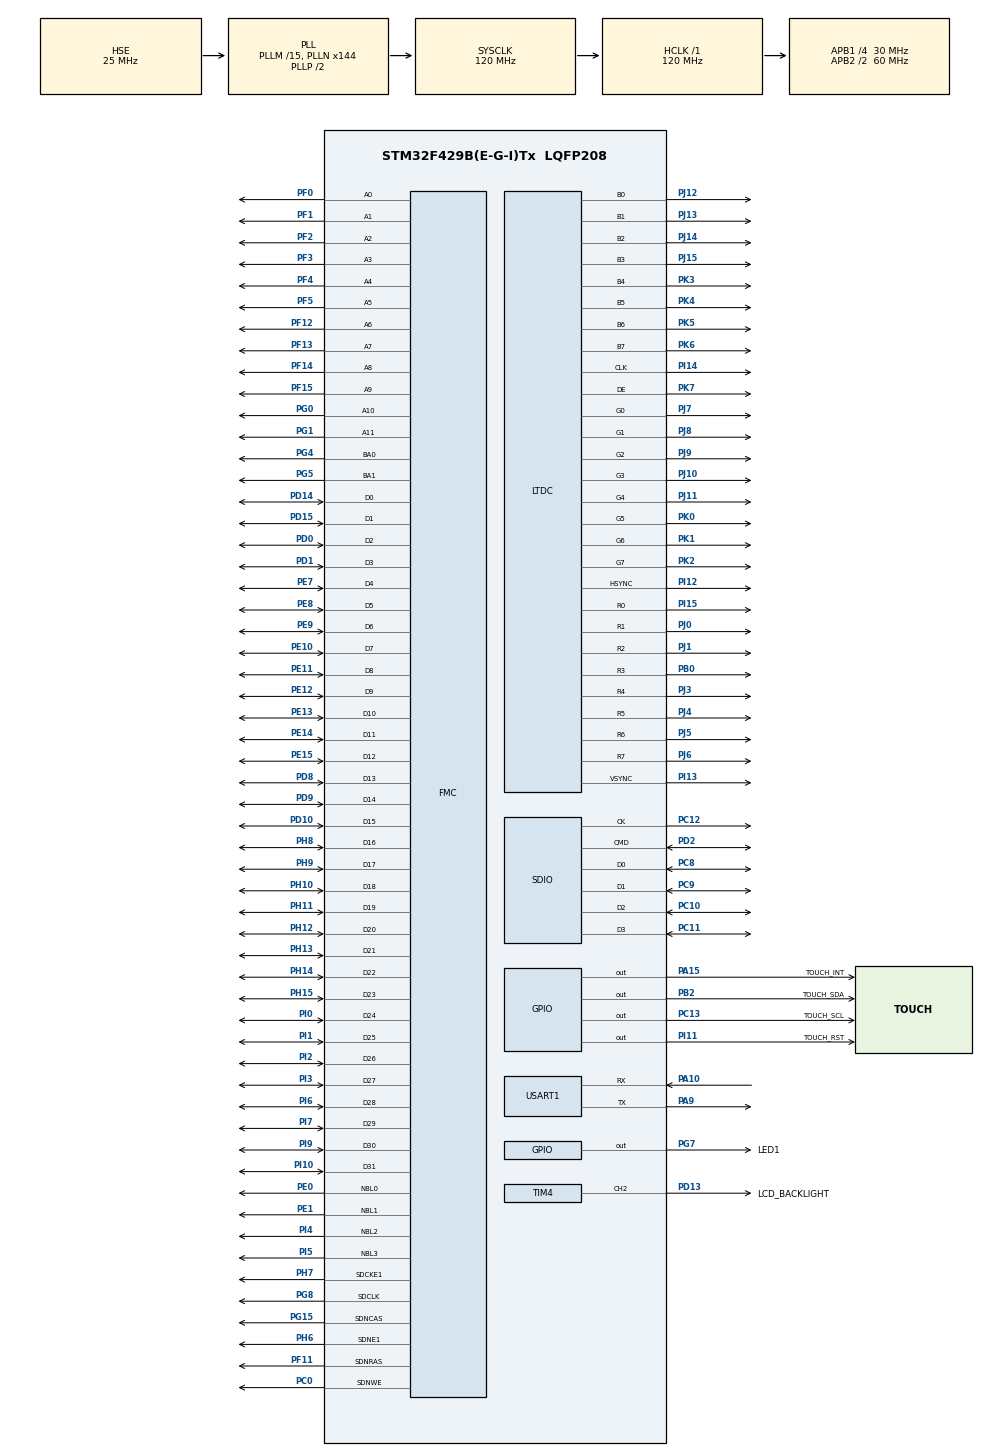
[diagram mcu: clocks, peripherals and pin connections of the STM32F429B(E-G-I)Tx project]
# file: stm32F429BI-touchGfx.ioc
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DMA2D.ColorMode=DMA2D_OUTPUT_RGB888
FMC.CASLatency1=FMC_SDRAM_CAS_LATENCY_3
FMC.ExitSelfRefreshDelay1=7
FMC.LoadToActiveDelay1=2
FMC.RCDDelay1=2
FMC.RPDelay1=2
FMC.RPDelay2=2
FMC.ReadBurst1=FMC_SDRAM_RBURST_ENABLE
FMC.ReadBurst2=FMC_SDRAM_RBURST_ENABLE
FMC.ReadPipeDelay1=FMC_SDRAM_RPIPE_DELAY_1
FMC.ReadPipeDelay2=FMC_SDRAM_RPIPE_DELAY_1
FMC.RowCycleDelay1=6
FMC.RowCycleDelay2=6
FMC.SDClockPeriod1=FMC_SDRAM_CLOCK_PERIOD_2
FMC.SDClockPeriod2=FMC_SDRAM_CLOCK_PERIOD_2
FMC.SelfRefreshTime1=4
FMC.WriteRecoveryTime1=2
FREERTOS.Tasks01=defaultTask,0,2048,StartDefaultTask,Default,NULL,Dynamic,NULL,NULL;blinkLed,-3,128,blinkingLed,Default,NULL,Dynamic,NULL,NULL
LTDC.ActiveW=800
LTDC.Alpha_L0=255
LTDC.FBStartAdress_L0=0xD0000000
LTDC.HBP=75
LTDC.HFP=180
LTDC.HSync=2
LTDC.ImageHeight_L0=480
LTDC.ImageWidth_L0=800
LTDC.Layers=0
LTDC.PixelFormat_L0=LTDC_PIXEL_FORMAT_RGB888
LTDC.VBP=22
LTDC.VFP=22
LTDC.VSync=2
LTDC.WindowX0_L0=0
LTDC.WindowX1_L0=800
LTDC.WindowY0_L0=0
LTDC.WindowY1_L0=480
Mcu.Family=STM32F4
Mcu.Name=STM32F429B(E-G-I)Tx
Mcu.Package=LQFP208
NVIC.DMA2D_IRQn=true\:5\:0\:false\:false\:true\:true\:true\:true
NVIC.LTDC_IRQn=true\:5\:0\:false\:false\:true\:true\:true\:true
NVIC.PriorityGroup=NVIC_PRIORITYGROUP_4
NVIC.SDIO_IRQn=true\:5\:0\:false\:false\:true\:true\:true\:true
NVIC.TIM1_UP_TIM10_IRQn=true\:0\:0\:false\:false\:true\:false\:false\:true
NVIC.TimeBase=TIM1_UP_TIM10_IRQn
NVIC.TimeBaseIP=TIM1
NVIC.USART1_IRQn=true\:5\:0\:false\:false\:true\:true\:true\:true
PA10.Mode=Asynchronous
PA10.Signal=USART1_RX
PA15.GPIO_Label=TOUCH_INT
PA15.GPIO_ModeDefaultOutputPP=GPIO_MODE_OUTPUT_OD
PA15.GPIO_PuPd=GPIO_NOPULL
PA15.PinState=GPIO_PIN_SET
PA15.Signal=GPIO_Output
PA9.Mode=Asynchronous
PA9.Signal=USART1_TX
PB0.Mode=RGB888
PB0.Signal=LTDC_R3
PB2/BOOT1.GPIO_Label=TOUCH_SDA
PB2/BOOT1.GPIO_ModeDefaultOutputPP=GPIO_MODE_OUTPUT_OD
PB2/BOOT1.GPIO_PuPd=GPIO_NOPULL
PB2/BOOT1.GPIO_Speed=GPIO_SPEED_FREQ_MEDIUM
PB2/BOOT1.PinState=GPIO_PIN_SET
PB2/BOOT1.Signal=GPIO_Output
PC0.Signal=FMC_SDNWE
PC10.Mode=SD_4_bits_Wide_bus
PC10.Signal=SDIO_D2
PC11.Mode=SD_4_bits_Wide_bus
PC11.Signal=SDIO_D3
PC12.Mode=SD_4_bits_Wide_bus
PC12.Signal=SDIO_CK
PC13.GPIO_Label=TOUCH_SCL
PC13.GPIO_ModeDefaultOutputPP=GPIO_MODE_OUTPUT_OD
PC13.GPIO_PuPd=GPIO_NOPULL
PC13.PinState=GPIO_PIN_SET
PC13.Signal=GPIO_Output
PC14/OSC32_IN.Mode=LSE-External-Oscillator
PC14/OSC32_IN.Signal=RCC_OSC32_IN
PC15/OSC32_OUT.Mode=LSE-External-Oscillator
PC15/OSC32_OUT.Signal=RCC_OSC32_OUT
PC8.Mode=SD_4_bits_Wide_bus
PC8.Signal=SDIO_D0
PC9.Mode=SD_4_bits_Wide_bus
PC9.Signal=SDIO_D1
PD0.Signal=FMC_D2_DA2
PD1.Signal=FMC_D3_DA3
PD10.Signal=FMC_D15_DA15
PD13.GPIO_Label=LCD_BACKLIGHT
PD13.GPIO_Speed=GPIO_SPEED_FREQ_HIGH
PD13.Signal=S_TIM4_CH2
PD14.Signal=FMC_D0_DA0
PD15.Signal=FMC_D1_DA1
PD2.Mode=SD_4_bits_Wide_bus
PD2.Signal=SDIO_CMD
PD8.Signal=FMC_D13_DA13
PD9.Signal=FMC_D14_DA14
PE0.Signal=FMC_NBL0
PE1.Signal=FMC_NBL1
PE10.Signal=FMC_D7_DA7
PE11.Signal=FMC_D8_DA8
PE12.Signal=FMC_D9_DA9
PE13.Signal=FMC_D10_DA10
PE14.Signal=FMC_D11_DA11
PE15.Signal=FMC_D12_DA12
PE7.Signal=FMC_D4_DA4
PE8.Signal=FMC_D5_DA5
PE9.Signal=FMC_D6_DA6
PF0.Signal=FMC_A0
PF1.Signal=FMC_A1
PF11.Signal=FMC_SDNRAS
PF12.Signal=FMC_A6
PF13.Signal=FMC_A7
PF14.Signal=FMC_A8
PF15.Signal=FMC_A9
PF2.Signal=FMC_A2
PF3.Signal=FMC_A3
PF4.Signal=FMC_A4
PF5.Signal=FMC_A5
PG0.Signal=FMC_A10
PG1.Signal=FMC_A11
PG15.Signal=FMC_SDNCAS
PG4.Signal=FMC_A14_BA0
PG5.Signal=FMC_A15_BA1
PG7.GPIO_Label=LED1
PG7.Signal=GPIO_Output
PG8.Signal=FMC_SDCLK
PH0/OSC_IN.Mode=HSE-External-Oscillator
PH0/OSC_IN.Signal=RCC_OSC_IN
PH1/OSC_OUT.Mode=HSE-External-Oscillator
PH1/OSC_OUT.Signal=RCC_OSC_OUT
PH10.Signal=FMC_D18
PH11.Signal=FMC_D19
PH12.Signal=FMC_D20
PH13.Signal=FMC_D21
PH14.Signal=FMC_D22
PH15.Signal=FMC_D23
PH6.Mode=SdramChipSelect2_1
PH6.Signal=FMC_SDNE1
PH7.Mode=SdramChipSelect2_1
PH7.Signal=FMC_SDCKE1
PH8.Signal=FMC_D16
PH9.Signal=FMC_D17
PI0.Signal=FMC_D24
PI1.Signal=FMC_D25
PI10.Signal=FMC_D31
PI11.GPIO_Label=TOUCH_RST
PI11.GPIO_ModeDefaultOutputPP=GPIO_MODE_OUTPUT_OD
PI11.GPIO_PuPd=GPIO_NOPULL
PI11.GPIO_Speed=GPIO_SPEED_FREQ_MEDIUM
PI11.PinState=GPIO_PIN_SET
PI11.Signal=GPIO_Output
PI12.Mode=RGB888
PI12.Signal=LTDC_HSYNC
PI13.Mode=RGB888
PI13.Signal=LTDC_VSYNC
PI14.Mode=RGB888
PI14.Signal=LTDC_CLK
PI15.Mode=RGB888
PI15.Signal=LTDC_R0
PI2.Signal=FMC_D26
PI3.Signal=FMC_D27
PI4.Signal=FMC_NBL2
PI5.Signal=FMC_NBL3
PI6.Signal=FMC_D28
PI7.Signal=FMC_D29
PI9.Signal=FMC_D30
PJ0.Mode=RGB888
PJ0.Signal=LTDC_R1
PJ1.Mode=RGB888
PJ1.Signal=LTDC_R2
PJ10.Mode=RGB888
PJ10.Signal=LTDC_G3
PJ11.Mode=RGB888
PJ11.Signal=LTDC_G4
PJ12.Mode=RGB888
PJ12.Signal=LTDC_B0
PJ13.Mode=RGB888
PJ13.Signal=LTDC_B1
PJ14.Mode=RGB888
PJ14.Signal=LTDC_B2
PJ15.Mode=RGB888
PJ15.Signal=LTDC_B3
PJ3.Mode=RGB888
PJ3.Signal=LTDC_R4
PJ4.Mode=RGB888
PJ4.Signal=LTDC_R5
PJ5.Mode=RGB888
PJ5.Signal=LTDC_R6
PJ6.Mode=RGB888
PJ6.Signal=LTDC_R7
PJ7.Mode=RGB888
PJ7.Signal=LTDC_G0
PJ8.Mode=RGB888
PJ8.Signal=LTDC_G1
PJ9.Mode=RGB888
PJ9.Signal=LTDC_G2
PK0.Mode=RGB888
PK0.Signal=LTDC_G5
PK1.Mode=RGB888
PK1.Signal=LTDC_G6
PK2.Mode=RGB888
PK2.Signal=LTDC_G7
PK3.Mode=RGB888
PK3.Signal=LTDC_B4
PK4.Mode=RGB888
PK4.Signal=LTDC_B5
PK5.Mode=RGB888
PK5.Signal=LTDC_B6
PK6.Mode=RGB888
PK6.Signal=LTDC_B7
PK7.Mode=RGB888
PK7.Signal=LTDC_DE
ProjectManager.HeapSize=0x200
ProjectManager.StackSize=0x400
ProjectManager.TargetToolchain=STM32CubeIDE
RCC.48MHZClocksFreq_Value=48000000
RCC.AHBFreq_Value=120000000
RCC.APB1CLKDivider=RCC_HCLK_DIV4
RCC.APB1Freq_Value=30000000
RCC.APB1TimFreq_Value=60000000
RCC.APB2CLKDivider=RCC_HCLK_DIV2
RCC.APB2Freq_Value=60000000
RCC.APB2TimFreq_Value=120000000
RCC.CortexFreq_Value=120000000
RCC.HCLKFreq_Value=120000000
RCC.HSE_VALUE=25000000
RCC.HSI_VALUE=16000000
RCC.PLLM=15
RCC.PLLN=144
RCC.PLLQ=5
RCC.PLLSAIN=60
RCC.PLLSourceVirtual=RCC_PLLSOURCE_HSE
RCC.SYSCLKFreq_VALUE=120000000
RCC.SYSCLKSource=RCC_SYSCLKSOURCE_PLLCLK
RCC.VCOOutputFreq_Value=240000000
SH.FMC_A0.0=FMC_A0,12b-sda1
SH.FMC_A1.0=FMC_A1,12b-sda1
SH.FMC_A10.0=FMC_A10,12b-sda1
SH.FMC_A11.0=FMC_A11,12b-sda1
SH.FMC_A14_BA0.0=FMC_BA0,FourSdramBanks1
SH.FMC_A15_BA1.0=FMC_BA1,FourSdramBanks1
SH.FMC_A2.0=FMC_A2,12b-sda1
SH.FMC_A3.0=FMC_A3,12b-sda1
SH.FMC_A4.0=FMC_A4,12b-sda1
SH.FMC_A5.0=FMC_A5,12b-sda1
SH.FMC_A6.0=FMC_A6,12b-sda1
SH.FMC_A7.0=FMC_A7,12b-sda1
SH.FMC_A8.0=FMC_A8,12b-sda1
SH.FMC_A9.0=FMC_A9,12b-sda1
SH.FMC_D0_DA0.0=FMC_D0,sd-32b-d1
SH.FMC_D10_DA10.0=FMC_D10,sd-32b-d1
SH.FMC_D11_DA11.0=FMC_D11,sd-32b-d1
SH.FMC_D12_DA12.0=FMC_D12,sd-32b-d1
SH.FMC_D13_DA13.0=FMC_D13,sd-32b-d1
SH.FMC_D14_DA14.0=FMC_D14,sd-32b-d1
SH.FMC_D15_DA15.0=FMC_D15,sd-32b-d1
SH.FMC_D16.0=FMC_D16,sd-32b-d1
SH.FMC_D17.0=FMC_D17,sd-32b-d1
SH.FMC_D18.0=FMC_D18,sd-32b-d1
SH.FMC_D19.0=FMC_D19,sd-32b-d1
SH.FMC_D1_DA1.0=FMC_D1,sd-32b-d1
SH.FMC_D20.0=FMC_D20,sd-32b-d1
SH.FMC_D21.0=FMC_D21,sd-32b-d1
SH.FMC_D22.0=FMC_D22,sd-32b-d1
SH.FMC_D23.0=FMC_D23,sd-32b-d1
SH.FMC_D24.0=FMC_D24,sd-32b-d1
SH.FMC_D25.0=FMC_D25,sd-32b-d1
SH.FMC_D26.0=FMC_D26,sd-32b-d1
SH.FMC_D27.0=FMC_D27,sd-32b-d1
SH.FMC_D28.0=FMC_D28,sd-32b-d1
SH.FMC_D29.0=FMC_D29,sd-32b-d1
SH.FMC_D2_DA2.0=FMC_D2,sd-32b-d1
SH.FMC_D30.0=FMC_D30,sd-32b-d1
SH.FMC_D31.0=FMC_D31,sd-32b-d1
SH.FMC_D3_DA3.0=FMC_D3,sd-32b-d1
SH.FMC_D4_DA4.0=FMC_D4,sd-32b-d1
SH.FMC_D5_DA5.0=FMC_D5,sd-32b-d1
SH.FMC_D6_DA6.0=FMC_D6,sd-32b-d1
SH.FMC_D7_DA7.0=FMC_D7,sd-32b-d1
SH.FMC_D8_DA8.0=FMC_D8,sd-32b-d1
SH.FMC_D9_DA9.0=FMC_D9,sd-32b-d1
SH.FMC_NBL0.0=FMC_NBL0,Sd4ByteEnable1
SH.FMC_NBL1.0=FMC_NBL1,Sd4ByteEnable1
SH.FMC_NBL2.0=FMC_NBL2,Sd4ByteEnable1
SH.FMC_NBL3.0=FMC_NBL3,Sd4ByteEnable1
SH.FMC_SDCLK.0=FMC_SDCLK,12b-sda1
SH.FMC_SDNCAS.0=FMC_SDNCAS,12b-sda1
SH.FMC_SDNRAS.0=FMC_SDNRAS,12b-sda1
SH.FMC_SDNWE.0=FMC_SDNWE,12b-sda1
SH.S_TIM4_CH2.0=TIM4_CH2,PWM Generation2 CH2
STMicroelectronics.X-CUBE-TOUCHGFX.4.13.0.ApplicationCcGraphicsJjApplication=TouchGFXOoGenerator
STMicroelectronics.X-CUBE-TOUCHGFX.4.13.0.tgfx_address1=0xD0000000
STMicroelectronics.X-CUBE-TOUCHGFX.4.13.0.tgfx_custom_height=480
STMicroelectronics.X-CUBE-TOUCHGFX.4.13.0.tgfx_display_interface=disp_ltdc
STMicroelectronics.X-CUBE-TOUCHGFX.4.13.0.tgfx_hardware_accelerator=dma_2d
STMicroelectronics.X-CUBE-TOUCHGFX.4.13.0.tgfx_location=By Address
STMicroelectronics.X-CUBE-TOUCHGFX.4.13.0.tgfx_ltdc_height=480
STMicroelectronics.X-CUBE-TOUCHGFX.4.13.0.tgfx_ltdc_width=800
STMicroelectronics.X-CUBE-TOUCHGFX.4.13.0.tgfx_pixel_format=RGB888\:24
STMicroelectronics.X-CUBE-TOUCHGFX.4.13.0.tgfx_vsync=vsync_ltdc
TIM4.AutoReloadPreload=TIM_AUTORELOAD_PRELOAD_DISABLE
TIM4.Channel-PWM\ Generation2\ CH2=TIM_CHANNEL_2
TIM4.OC2Preload_PWM=DISABLE
TIM4.OCFastMode_PWM-PWM\ Generation2\ CH2=TIM_OCFAST_ENABLE
TIM4.Period=1024
TIM4.Prescaler=15
TIM4.Pulse-PWM\ Generation2\ CH2=512
USART1.VirtualMode=VM_ASYNC
VP_CRC_VS_CRC.Mode=CRC_Activate
VP_DMA2D_VS_DMA2D.Mode=DMA2D_Activate
VP_FREERTOS_VS_CMSIS_V1.Mode=CMSIS_V1
VP_STMicroelectronics.X-CUBE-TOUCHGFX_VS_GraphicsJjApplication_4.13.0.Mode=GraphicsJjApplication
VP_SYS_VS_tim1.Mode=TIM1
VP_TIM4_VS_ClockSourceINT.Mode=Internal
board=custom

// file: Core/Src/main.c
/* USER CODE BEGIN Header */
/**
  ******************************************************************************
  * @file           : main.c
  * @brief          : Main program body
  ******************************************************************************
  * @attention
  *
  * <h2><center>&copy; Copyright (c) 2020 STMicroelectronics.
  * All rights reserved.</center></h2>
  *
  * This software component is licensed by ST under BSD 3-Clause license,
  * the "License"; You may not use this file except in compliance with the
  * License. You may obtain a copy of the License at:
  *                        opensource.org/licenses/BSD-3-Clause
  *
  ******************************************************************************
  */
/* USER CODE END Header */

#include "main.h"
#include "cmsis_os.h"
#include "app_touchgfx.h"

/* USER CODE BEGIN PD */
#define REFRESH_COUNT        1386
#define SDRAM_BANK_ADDR     ((uint32_t)0xD0000000)                      // FMC SDRAM address
#define SDRAM_Size 0x01000000  //16MB

#define SDRAM_TIMEOUT                            ((uint32_t)0xFFFF)
#define SDRAM_MODEREG_BURST_LENGTH_1             ((uint16_t)0x0000)
#define SDRAM_MODEREG_BURST_LENGTH_2             ((uint16_t)0x0001)
#define SDRAM_MODEREG_BURST_LENGTH_4             ((uint16_t)0x0002)
#define SDRAM_MODEREG_BURST_LENGTH_8             ((uint16_t)0x0004)
#define SDRAM_MODEREG_BURST_TYPE_SEQUENTIAL      ((uint16_t)0x0000)
#define SDRAM_MODEREG_BURST_TYPE_INTERLEAVED     ((uint16_t)0x0008)
#define SDRAM_MODEREG_CAS_LATENCY_2              ((uint16_t)0x0020)
#define SDRAM_MODEREG_CAS_LATENCY_3              ((uint16_t)0x0030)
#define SDRAM_MODEREG_OPERATING_MODE_STANDARD    ((uint16_t)0x0000)
#define SDRAM_MODEREG_WRITEBURST_MODE_PROGRAMMED ((uint16_t)0x0000)
#define SDRAM_MODEREG_WRITEBURST_MODE_SINGLE     ((uint16_t)0x0200)
/* USER CODE END PD */

CRC_HandleTypeDef hcrc;

DMA2D_HandleTypeDef hdma2d;

LTDC_HandleTypeDef hltdc;

SD_HandleTypeDef hsd;

TIM_HandleTypeDef htim4;

UART_HandleTypeDef huart1;

SDRAM_HandleTypeDef hsdram1;

osThreadId defaultTaskHandle;
osThreadId blinkLedHandle;
/* USER CODE BEGIN PV */
static FMC_SDRAM_CommandTypeDef Command;
/* USER CODE END PV */

void SystemClock_Config(void);
static void MX_GPIO_Init(void);
static void MX_CRC_Init(void);
static void MX_DMA2D_Init(void);
static void MX_FMC_Init(void);
static void MX_LTDC_Init(void);
static void MX_TIM4_Init(void);
static void MX_USART1_UART_Init(void);
static void MX_SDIO_SD_Init(void);
void StartDefaultTask(void const * argument);
void blinkingLed(void const * argument);

int main(void)
{

  /* MCU Configuration--------------------------------------------------------*/

  /* Reset of all peripherals, Initializes the Flash interface and the Systick. */
  HAL_Init();

  /* Configure the system clock */
  SystemClock_Config();

  /* USER CODE BEGIN SysInit */
  SystemCoreClockUpdate(); // from https://support.touchgfx.com/docs/development/board-bring-up/how-to/02-cpu-running
  /* USER CODE END SysInit */

  /* Initialize all configured peripherals */
  MX_GPIO_Init();
  MX_CRC_Init();
  MX_DMA2D_Init();
  MX_FMC_Init();
  MX_LTDC_Init();
  MX_TIM4_Init();
  MX_USART1_UART_Init();
  MX_SDIO_SD_Init();
  MX_TouchGFX_Init();
  /* USER CODE BEGIN 2 */
  printf("System configured!\r\n");
  /* USER CODE END 2 */

  /* Create the thread(s) */
  /* definition and creation of defaultTask */
  osThreadDef(defaultTask, StartDefaultTask, osPriorityNormal, 0, 2048);
  defaultTaskHandle = osThreadCreate(osThread(defaultTask), NULL);

  /* definition and creation of blinkLed */
  osThreadDef(blinkLed, blinkingLed, osPriorityIdle, 0, 128);
  blinkLedHandle = osThreadCreate(osThread(blinkLed), NULL);

  /* Start scheduler */
  osKernelStart();

  /* We should never get here as control is now taken by the scheduler */
  /* Infinite loop */
  while (1)
  {

  }
}

void SystemClock_Config(void)
{
  RCC_OscInitTypeDef RCC_OscInitStruct = {0};
  RCC_ClkInitTypeDef RCC_ClkInitStruct = {0};
  RCC_PeriphCLKInitTypeDef PeriphClkInitStruct = {0};

  /** Configure the main internal regulator output voltage
  */
  __HAL_RCC_PWR_CLK_ENABLE();
  __HAL_PWR_VOLTAGESCALING_CONFIG(PWR_REGULATOR_VOLTAGE_SCALE3);
  /** Initializes the CPU, AHB and APB busses clocks
  */
  RCC_OscInitStruct.OscillatorType = RCC_OSCILLATORTYPE_HSE;
  RCC_OscInitStruct.HSEState = RCC_HSE_ON;
  RCC_OscInitStruct.PLL.PLLState = RCC_PLL_ON;
  RCC_OscInitStruct.PLL.PLLSource = RCC_PLLSOURCE_HSE;
  RCC_OscInitStruct.PLL.PLLM = 15;
  RCC_OscInitStruct.PLL.PLLN = 144;
  RCC_OscInitStruct.PLL.PLLP = RCC_PLLP_DIV2;
  RCC_OscInitStruct.PLL.PLLQ = 5;
  if (HAL_RCC_OscConfig(&RCC_OscInitStruct) != HAL_OK)
  {
    Error_Handler();
  }
  /** Initializes the CPU, AHB and APB busses clocks
  */
  RCC_ClkInitStruct.ClockType = RCC_CLOCKTYPE_HCLK|RCC_CLOCKTYPE_SYSCLK
                              |RCC_CLOCKTYPE_PCLK1|RCC_CLOCKTYPE_PCLK2;
  RCC_ClkInitStruct.SYSCLKSource = RCC_SYSCLKSOURCE_PLLCLK;
  RCC_ClkInitStruct.AHBCLKDivider = RCC_SYSCLK_DIV1;
  RCC_ClkInitStruct.APB1CLKDivider = RCC_HCLK_DIV4;
  RCC_ClkInitStruct.APB2CLKDivider = RCC_HCLK_DIV2;

  if (HAL_RCC_ClockConfig(&RCC_ClkInitStruct, FLASH_LATENCY_3) != HAL_OK)
  {
    Error_Handler();
  }
  PeriphClkInitStruct.PeriphClockSelection = RCC_PERIPHCLK_LTDC;
  PeriphClkInitStruct.PLLSAI.PLLSAIN = 60;
  PeriphClkInitStruct.PLLSAI.PLLSAIR = 2;
  PeriphClkInitStruct.PLLSAIDivR = RCC_PLLSAIDIVR_2;
  if (HAL_RCCEx_PeriphCLKConfig(&PeriphClkInitStruct) != HAL_OK)
  {
    Error_Handler();
  }
}

static void MX_CRC_Init(void)
{

  hcrc.Instance = CRC;
  if (HAL_CRC_Init(&hcrc) != HAL_OK)
  {
    Error_Handler();
  }

}

static void MX_DMA2D_Init(void)
{

  hdma2d.Instance = DMA2D;
  hdma2d.Init.Mode = DMA2D_M2M;
  hdma2d.Init.ColorMode = DMA2D_OUTPUT_RGB888;
  hdma2d.Init.OutputOffset = 0;
  hdma2d.LayerCfg[1].InputOffset = 0;
  hdma2d.LayerCfg[1].InputColorMode = DMA2D_INPUT_RGB888;
  hdma2d.LayerCfg[1].AlphaMode = DMA2D_NO_MODIF_ALPHA;
  hdma2d.LayerCfg[1].InputAlpha = 0;
  if (HAL_DMA2D_Init(&hdma2d) != HAL_OK)
  {
    Error_Handler();
  }
  if (HAL_DMA2D_ConfigLayer(&hdma2d, 1) != HAL_OK)
  {
    Error_Handler();
  }

}

static void MX_LTDC_Init(void)
{

  LTDC_LayerCfgTypeDef pLayerCfg = {0};

  hltdc.Instance = LTDC;
  hltdc.Init.HSPolarity = LTDC_HSPOLARITY_AL;
  hltdc.Init.VSPolarity = LTDC_VSPOLARITY_AL;
  hltdc.Init.DEPolarity = LTDC_DEPOLARITY_AL;
  hltdc.Init.PCPolarity = LTDC_PCPOLARITY_IPC;
  hltdc.Init.HorizontalSync = 1;
  hltdc.Init.VerticalSync = 1;
  hltdc.Init.AccumulatedHBP = 76;
  hltdc.Init.AccumulatedVBP = 23;
  hltdc.Init.AccumulatedActiveW = 876;
  hltdc.Init.AccumulatedActiveH = 503;
  hltdc.Init.TotalWidth = 1056;
  hltdc.Init.TotalHeigh = 525;
  hltdc.Init.Backcolor.Blue = 0;
  hltdc.Init.Backcolor.Green = 0;
  hltdc.Init.Backcolor.Red = 0;
  if (HAL_LTDC_Init(&hltdc) != HAL_OK)
  {
    Error_Handler();
  }
  pLayerCfg.WindowX0 = 0;
  pLayerCfg.WindowX1 = 800;
  pLayerCfg.WindowY0 = 0;
  pLayerCfg.WindowY1 = 480;
  pLayerCfg.PixelFormat = LTDC_PIXEL_FORMAT_RGB888;
  pLayerCfg.Alpha = 255;
  pLayerCfg.Alpha0 = 0;
  pLayerCfg.BlendingFactor1 = LTDC_BLENDING_FACTOR1_CA;
  pLayerCfg.BlendingFactor2 = LTDC_BLENDING_FACTOR2_CA;
  pLayerCfg.FBStartAdress = 0xD0000000;
  pLayerCfg.ImageWidth = 800;
  pLayerCfg.ImageHeight = 480;
  pLayerCfg.Backcolor.Blue = 0;
  pLayerCfg.Backcolor.Green = 0;
  pLayerCfg.Backcolor.Red = 0;
  if (HAL_LTDC_ConfigLayer(&hltdc, &pLayerCfg, 0) != HAL_OK)
  {
    Error_Handler();
  }

}

static void MX_SDIO_SD_Init(void)
{

  hsd.Instance = SDIO;
  hsd.Init.ClockEdge = SDIO_CLOCK_EDGE_RISING;
  hsd.Init.ClockBypass = SDIO_CLOCK_BYPASS_DISABLE;
  hsd.Init.ClockPowerSave = SDIO_CLOCK_POWER_SAVE_DISABLE;
  hsd.Init.BusWide = SDIO_BUS_WIDE_1B;
  hsd.Init.HardwareFlowControl = SDIO_HARDWARE_FLOW_CONTROL_DISABLE;
  hsd.Init.ClockDiv = 0;
  if (HAL_SD_Init(&hsd) != HAL_OK)
  {
    Error_Handler();
  }
  if (HAL_SD_ConfigWideBusOperation(&hsd, SDIO_BUS_WIDE_4B) != HAL_OK)
  {
    Error_Handler();
  }

}

static void MX_TIM4_Init(void)
{

  TIM_ClockConfigTypeDef sClockSourceConfig = {0};
  TIM_MasterConfigTypeDef sMasterConfig = {0};
  TIM_OC_InitTypeDef sConfigOC = {0};

  htim4.Instance = TIM4;
  htim4.Init.Prescaler = 15;
  htim4.Init.CounterMode = TIM_COUNTERMODE_UP;
  htim4.Init.Period = 1024;
  htim4.Init.ClockDivision = TIM_CLOCKDIVISION_DIV1;
  htim4.Init.AutoReloadPreload = TIM_AUTORELOAD_PRELOAD_DISABLE;
  if (HAL_TIM_Base_Init(&htim4) != HAL_OK)
  {
    Error_Handler();
  }
  sClockSourceConfig.ClockSource = TIM_CLOCKSOURCE_INTERNAL;
  if (HAL_TIM_ConfigClockSource(&htim4, &sClockSourceConfig) != HAL_OK)
  {
    Error_Handler();
  }
  if (HAL_TIM_PWM_Init(&htim4) != HAL_OK)
  {
    Error_Handler();
  }
  sMasterConfig.MasterOutputTrigger = TIM_TRGO_RESET;
  sMasterConfig.MasterSlaveMode = TIM_MASTERSLAVEMODE_DISABLE;
  if (HAL_TIMEx_MasterConfigSynchronization(&htim4, &sMasterConfig) != HAL_OK)
  {
    Error_Handler();
  }
  sConfigOC.OCMode = TIM_OCMODE_PWM1;
  sConfigOC.Pulse = 512;
  sConfigOC.OCPolarity = TIM_OCPOLARITY_HIGH;
  sConfigOC.OCFastMode = TIM_OCFAST_ENABLE;
  if (HAL_TIM_PWM_ConfigChannel(&htim4, &sConfigOC, TIM_CHANNEL_2) != HAL_OK)
  {
    Error_Handler();
  }
  __HAL_TIM_DISABLE_OCxPRELOAD(&htim4, TIM_CHANNEL_2);
  HAL_TIM_MspPostInit(&htim4);

}

static void MX_USART1_UART_Init(void)
{

  huart1.Instance = USART1;
  huart1.Init.BaudRate = 115200;
  huart1.Init.WordLength = UART_WORDLENGTH_8B;
  huart1.Init.StopBits = UART_STOPBITS_1;
  huart1.Init.Parity = UART_PARITY_NONE;
  huart1.Init.Mode = UART_MODE_TX_RX;
  huart1.Init.HwFlowCtl = UART_HWCONTROL_NONE;
  huart1.Init.OverSampling = UART_OVERSAMPLING_16;
  if (HAL_UART_Init(&huart1) != HAL_OK)
  {
    Error_Handler();
  }

}

/* FMC initialization function */
static void MX_FMC_Init(void)
{

  FMC_SDRAM_TimingTypeDef SdramTiming = {0};

  /** Perform the SDRAM1 memory initialization sequence
  */
  hsdram1.Instance = FMC_SDRAM_DEVICE;
  /* hsdram1.Init */
  hsdram1.Init.SDBank = FMC_SDRAM_BANK2;
  hsdram1.Init.ColumnBitsNumber = FMC_SDRAM_COLUMN_BITS_NUM_8;
  hsdram1.Init.RowBitsNumber = FMC_SDRAM_ROW_BITS_NUM_12;
  hsdram1.Init.MemoryDataWidth = FMC_SDRAM_MEM_BUS_WIDTH_32;
  hsdram1.Init.InternalBankNumber = FMC_SDRAM_INTERN_BANKS_NUM_4;
  hsdram1.Init.CASLatency = FMC_SDRAM_CAS_LATENCY_3;
  hsdram1.Init.WriteProtection = FMC_SDRAM_WRITE_PROTECTION_DISABLE;
  hsdram1.Init.SDClockPeriod = FMC_SDRAM_CLOCK_PERIOD_2;
  hsdram1.Init.ReadBurst = FMC_SDRAM_RBURST_ENABLE;
  hsdram1.Init.ReadPipeDelay = FMC_SDRAM_RPIPE_DELAY_1;
  /* SdramTiming */
  SdramTiming.LoadToActiveDelay = 2;
  SdramTiming.ExitSelfRefreshDelay = 7;
  SdramTiming.SelfRefreshTime = 4;
  SdramTiming.RowCycleDelay = 6;
  SdramTiming.WriteRecoveryTime = 2;
  SdramTiming.RPDelay = 2;
  SdramTiming.RCDDelay = 2;

  if (HAL_SDRAM_Init(&hsdram1, &SdramTiming) != HAL_OK)
  {
    Error_Handler( );
  }

  /* USER CODE BEGIN FMC_Init 2 */
  __IO uint32_t tmpmrd = 0;

  /* Step 1: Configure a clock configuration enable command */
  Command.CommandMode            = FMC_SDRAM_CMD_CLK_ENABLE;
  Command.CommandTarget          =  FMC_SDRAM_CMD_TARGET_BANK2;
  Command.AutoRefreshNumber      = 1;
  Command.ModeRegisterDefinition = 0;

  /* Send the command */
  HAL_SDRAM_SendCommand(&hsdram1, &Command, SDRAM_TIMEOUT);

  /* Step 2: Insert 100 us minimum delay */
  /* Inserted delay is equal to 1 ms due to systick time base unit (ms) */
  HAL_Delay(1);

  /* Step 3: Configure a PALL (precharge all) command */
  Command.CommandMode            = FMC_SDRAM_CMD_PALL;
  Command.CommandTarget          = FMC_SDRAM_CMD_TARGET_BANK2;
  Command.AutoRefreshNumber      = 1;
  Command.ModeRegisterDefinition = 0;

  /* Send the command */
  HAL_SDRAM_SendCommand(&hsdram1, &Command, SDRAM_TIMEOUT);

  /* Step 4: Configure an Auto Refresh command */
  Command.CommandMode            = FMC_SDRAM_CMD_AUTOREFRESH_MODE;
  Command.CommandTarget          = FMC_SDRAM_CMD_TARGET_BANK2;
  Command.AutoRefreshNumber      = 8;
  Command.ModeRegisterDefinition = 0;

  /* Send the command */
  HAL_SDRAM_SendCommand(&hsdram1, &Command, SDRAM_TIMEOUT);

  /* Step 5: Program the external memory mode register */
  tmpmrd = (uint32_t)SDRAM_MODEREG_BURST_LENGTH_2 | \
           SDRAM_MODEREG_BURST_TYPE_SEQUENTIAL    | \
           SDRAM_MODEREG_CAS_LATENCY_3            | \
           SDRAM_MODEREG_OPERATING_MODE_STANDARD  | \
           SDRAM_MODEREG_WRITEBURST_MODE_SINGLE;

  Command.CommandMode            = FMC_SDRAM_CMD_LOAD_MODE;
  Command.CommandTarget          = FMC_SDRAM_CMD_TARGET_BANK2;
  Command.AutoRefreshNumber      = 1;
  Command.ModeRegisterDefinition = tmpmrd;

  /* Send the command */
  HAL_SDRAM_SendCommand(&hsdram1, &Command, SDRAM_TIMEOUT);

  /* Step 6: Set the refresh rate counter */
  /* Set the device refresh rate */
  HAL_SDRAM_ProgramRefreshRate(&hsdram1, REFRESH_COUNT);

  //Deactivate speculative/cache access to first FMC Bank to save FMC bandwidth
  FMC_Bank1->BTCR[0] = 0x000030D2;
  /* USER CODE END FMC_Init 2 */
}

static void MX_GPIO_Init(void)
{
  GPIO_InitTypeDef GPIO_InitStruct = {0};

  /* GPIO Ports Clock Enable */
  __HAL_RCC_GPIOC_CLK_ENABLE();
  __HAL_RCC_GPIOI_CLK_ENABLE();
  __HAL_RCC_GPIOF_CLK_ENABLE();
  __HAL_RCC_GPIOH_CLK_ENABLE();
  __HAL_RCC_GPIOB_CLK_ENABLE();
  __HAL_RCC_GPIOJ_CLK_ENABLE();
  __HAL_RCC_GPIOG_CLK_ENABLE();
  __HAL_RCC_GPIOE_CLK_ENABLE();
  __HAL_RCC_GPIOD_CLK_ENABLE();
  __HAL_RCC_GPIOK_CLK_ENABLE();
  __HAL_RCC_GPIOA_CLK_ENABLE();

  /*Configure GPIO pin Output Level */
  HAL_GPIO_WritePin(TOUCH_SCL_GPIO_Port, TOUCH_SCL_Pin, GPIO_PIN_SET);

  /*Configure GPIO pin Output Level */
  HAL_GPIO_WritePin(TOUCH_RST_GPIO_Port, TOUCH_RST_Pin, GPIO_PIN_SET);

  /*Configure GPIO pin Output Level */
  HAL_GPIO_WritePin(TOUCH_SDA_GPIO_Port, TOUCH_SDA_Pin, GPIO_PIN_SET);

  /*Configure GPIO pin Output Level */
  HAL_GPIO_WritePin(LED1_GPIO_Port, LED1_Pin, GPIO_PIN_RESET);

  /*Configure GPIO pin Output Level */
  HAL_GPIO_WritePin(TOUCH_INT_GPIO_Port, TOUCH_INT_Pin, GPIO_PIN_SET);

  /*Configure GPIO pin : TOUCH_SCL_Pin */
  GPIO_InitStruct.Pin = TOUCH_SCL_Pin;
  GPIO_InitStruct.Mode = GPIO_MODE_OUTPUT_OD;
  GPIO_InitStruct.Pull = GPIO_NOPULL;
  GPIO_InitStruct.Speed = GPIO_SPEED_FREQ_LOW;
  HAL_GPIO_Init(TOUCH_SCL_GPIO_Port, &GPIO_InitStruct);

  /*Configure GPIO pin : TOUCH_RST_Pin */
  GPIO_InitStruct.Pin = TOUCH_RST_Pin;
  GPIO_InitStruct.Mode = GPIO_MODE_OUTPUT_OD;
  GPIO_InitStruct.Pull = GPIO_NOPULL;
  GPIO_InitStruct.Speed = GPIO_SPEED_FREQ_MEDIUM;
  HAL_GPIO_Init(TOUCH_RST_GPIO_Port, &GPIO_InitStruct);

  /*Configure GPIO pin : TOUCH_SDA_Pin */
  GPIO_InitStruct.Pin = TOUCH_SDA_Pin;
  GPIO_InitStruct.Mode = GPIO_MODE_OUTPUT_OD;
  GPIO_InitStruct.Pull = GPIO_NOPULL;
  GPIO_InitStruct.Speed = GPIO_SPEED_FREQ_MEDIUM;
  HAL_GPIO_Init(TOUCH_SDA_GPIO_Port, &GPIO_InitStruct);

  /*Configure GPIO pin : LED1_Pin */
  GPIO_InitStruct.Pin = LED1_Pin;
  GPIO_InitStruct.Mode = GPIO_MODE_OUTPUT_PP;
  GPIO_InitStruct.Pull = GPIO_NOPULL;
  GPIO_InitStruct.Speed = GPIO_SPEED_FREQ_LOW;
  HAL_GPIO_Init(LED1_GPIO_Port, &GPIO_InitStruct);

  /*Configure GPIO pin : TOUCH_INT_Pin */
  GPIO_InitStruct.Pin = TOUCH_INT_Pin;
  GPIO_InitStruct.Mode = GPIO_MODE_OUTPUT_OD;
  GPIO_InitStruct.Pull = GPIO_NOPULL;
  GPIO_InitStruct.Speed = GPIO_SPEED_FREQ_LOW;
  HAL_GPIO_Init(TOUCH_INT_GPIO_Port, &GPIO_InitStruct);

}

void StartDefaultTask(void const * argument)
{
  /* USER CODE BEGIN 5 */
  HAL_TIM_PWM_Start(&htim4, TIM_CHANNEL_2);
  MX_TouchGFX_Process();
  /* Infinite loop */
  for(;;)
  {
    osDelay(1);
  }
  /* USER CODE END 5 */
}

void blinkingLed(void const * argument)
{
  /* USER CODE BEGIN blinkingLed */
  int err = 0;
  /* Infinite loop */
  for(;;)
  {
#if 0
      //printf("STM32F429 SDRAM test\r\n");
      for (i = 0; i < SDRAM_Size/4; i++)
      {
              *(__IO uint32_t*) (SDRAM_BANK_ADDR + 4*i) = i;
      }

      //printf("check values\r\n");

      for(i = 0; i < SDRAM_Size/4;i++ )
      {
              ReadData = *(__IO uint32_t*)(SDRAM_BANK_ADDR + 4 * i );
              if( ReadData != i )
              {
            	  if (!err) {
            		  err = 1;
                      //printf("SDRAM fail\r\n");
                      HAL_GPIO_WritePin(LED1_GPIO_Port, LED1_Pin, GPIO_PIN_RESET);
            	  }
              }
      }
      int now = HAL_GetTick();
      diff2 = now - last;
      last = now;
#endif
      if (err)
          HAL_GPIO_WritePin(LED1_GPIO_Port, LED1_Pin, GPIO_PIN_SET); // keep led1 off on SRAM ERR
      else
          HAL_GPIO_WritePin(LED1_GPIO_Port, LED1_Pin, GPIO_PIN_RESET);
      osDelay(100);
      HAL_GPIO_WritePin(LED1_GPIO_Port, LED1_Pin, GPIO_PIN_SET);
      osDelay(100);
  }
  /* USER CODE END blinkingLed */
}

 /**
  * @brief  Period elapsed callback in non blocking mode
  * @note   This function is called  when TIM1 interrupt took place, inside
  * HAL_TIM_IRQHandler(). It makes a direct call to HAL_IncTick() to increment
  * a global variable "uwTick" used as application time base.
  * @param  htim : TIM handle
  * @retval None
  */
void HAL_TIM_PeriodElapsedCallback(TIM_HandleTypeDef *htim)
{
  if (htim->Instance == TIM1) {
    HAL_IncTick();
  }
}

void Error_Handler(void)
{
}

/************************ (C) COPYRIGHT STMicroelectronics *****END OF FILE****/
